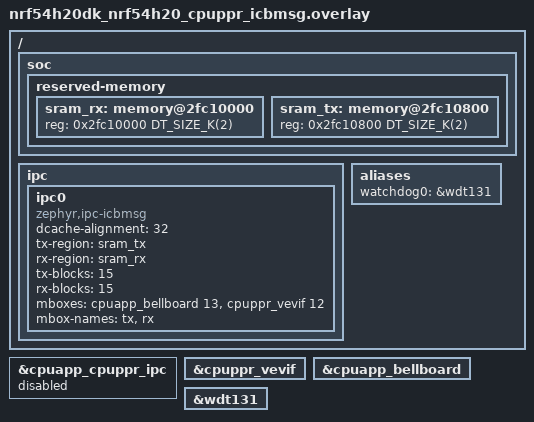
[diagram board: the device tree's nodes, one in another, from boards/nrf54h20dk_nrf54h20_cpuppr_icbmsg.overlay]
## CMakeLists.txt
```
#
# Copyright (c) 2026 Nordic Semiconductor ASA
#
# SPDX-License-Identifier: Apache-2.0
#

cmake_minimum_required(VERSION 3.20.0)

find_package(Zephyr REQUIRED HINTS $ENV{ZEPHYR_BASE})
project(ipc_service_remote)

target_include_directories(app PRIVATE ${CMAKE_CURRENT_SOURCE_DIR}/../common)

target_sources(app PRIVATE src/main.c)
```

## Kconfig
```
source "Kconfig.zephyr"

config TEST_MULTI_ENDPOINT
	bool
	default y if $(dt_nodelabel_has_compat,ipc0,$(DT_COMPAT_ZEPHYR_IPC_ICBMSG))
	default n
```

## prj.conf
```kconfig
CONFIG_IPC_SERVICE=y
CONFIG_MBOX=y
CONFIG_LOG=y
CONFIG_GPIO=n
CONFIG_CPU_LOAD=y
```

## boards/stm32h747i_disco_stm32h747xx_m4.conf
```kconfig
CONFIG_CONSOLE=y
CONFIG_UART_CONSOLE=y
CONFIG_LOG_BACKEND_UART=y

CONFIG_MBOX_STM32_HSEM=y
```

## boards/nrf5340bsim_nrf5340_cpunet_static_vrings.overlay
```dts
/*
 * Copyright (c) 2026 Nordic Semiconductor ASA
 *
 * SPDX-License-Identifier: Apache-2.0
 */

#include "nrf5340dk_nrf5340_cpunet_static_vrings.overlay"
```

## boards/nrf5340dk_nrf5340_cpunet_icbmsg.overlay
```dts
/*
 * Copyright (c) 2026 Nordic Semiconductor ASA
 *
 * SPDX-License-Identifier: Apache-2.0
 */

#include "nrf5340dk_nrf5340_cpunet_common.dtsi"

/ {
	reserved-memory {
		ranges;
		#address-cells = <1>;
		#size-cells = <1>;

		sram_rx: memory@20070000 {
			reg = <0x20070000 DT_SIZE_K(32)>;
		};

		sram_tx: memory@20078000 {
			reg = <0x20078000 DT_SIZE_K(32)>;
		};
	};

	ipc0: ipc0 {
		compatible = "zephyr,ipc-icbmsg";
		dcache-alignment = <8>;
		tx-region = <&sram_tx>;
		rx-region = <&sram_rx>;
		tx-blocks = <20>;
		rx-blocks = <20>;
		mboxes = <&mbox 0>, <&mbox 1>;
		mbox-names = "rx", "tx";
		status = "okay";
	};
};
```

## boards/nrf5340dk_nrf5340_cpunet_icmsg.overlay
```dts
/*
 * Copyright (c) 2026 Nordic Semiconductor ASA
 *
 * SPDX-License-Identifier: Apache-2.0
 */

#include "nrf5340dk_nrf5340_cpunet_common.dtsi"

/ {
	reserved-memory {
		ranges;
		#address-cells = <1>;
		#size-cells = <1>;

		sram_rx: memory@20070000 {
			reg = <0x20070000 DT_SIZE_K(32)>;
		};

		sram_tx: memory@20078000 {
			reg = <0x20078000 DT_SIZE_K(32)>;
		};
	};

	ipc0: ipc0 {
		compatible = "zephyr,ipc-icmsg";
		dcache-alignment = <8>;
		tx-region = <&sram_tx>;
		rx-region = <&sram_rx>;
		mboxes = <&mbox 0>, <&mbox 1>;
		mbox-names = "rx", "tx";
		status = "okay";
	};
};
```

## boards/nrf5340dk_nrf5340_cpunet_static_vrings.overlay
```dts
/*
 * Copyright (c) 2026 Nordic Semiconductor ASA
 *
 * SPDX-License-Identifier: Apache-2.0
 */

#include <zephyr/dt-bindings/ipc_service/static_vrings.h>

/delete-node/ &ipc0;

/ {
	reserved-memory {
		#address-cells = <1>;
		#size-cells = <1>;

		sram_ipc0: memory@20070000 {
			reg = <0x20070000 DT_SIZE_K(8)>;
		};
	};

	ipc0: ipc0 {
		compatible = "zephyr,ipc-openamp-static-vrings";
		memory-region = <&sram_ipc0>;
		mboxes = <&mbox 0>, <&mbox 1>;
		mbox-names = "rx", "tx";
		role = "remote";
		zephyr,buffer-size = <128>;
		status = "okay";
	};
};
```

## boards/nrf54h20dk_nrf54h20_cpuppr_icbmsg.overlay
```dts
/*
 * Copyright (c) 2026 Nordic Semiconductor ASA
 *
 * SPDX-License-Identifier: Apache-2.0
 */

&cpuapp_cpuppr_ipc {
	status = "disabled";
};

/ {
	soc {
		reserved-memory {
			#address-cells = <1>;
			#size-cells = <1>;

			sram_rx: memory@2fc10000 {
				reg = <0x2fc10000 DT_SIZE_K(2)>;
			};

			sram_tx: memory@2fc10800 {
				reg = <0x2fc10800 DT_SIZE_K(2)>;
			};
		};
	};

	ipc {
		ipc0: ipc0 {
			compatible = "zephyr,ipc-icbmsg";
			dcache-alignment = <32>;
			tx-region = <&sram_tx>;
			rx-region = <&sram_rx>;
			tx-blocks = <15>;
			rx-blocks = <15>;
			mboxes = <&cpuapp_bellboard 13>, <&cpuppr_vevif 12>;
			mbox-names = "tx", "rx";
			status = "okay";
		};
	};
};

&cpuppr_vevif {
	status = "okay";
};

&cpuapp_bellboard {
	status = "okay";
};

&wdt131 {
	status = "okay";
};

/ {
	aliases {
		watchdog0 = &wdt131;
	};
};
```

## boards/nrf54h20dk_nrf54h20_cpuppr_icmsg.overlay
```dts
/*
 * Copyright (c) 2026 Nordic Semiconductor ASA
 *
 * SPDX-License-Identifier: Apache-2.0
 */

ipc0: &cpuapp_cpuppr_ipc {
	compatible = "zephyr,ipc-icmsg";
	/delete-property/ tx-blocks;
	/delete-property/ rx-blocks;
};
```

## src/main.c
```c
/*
 * Copyright (c) 2026 Nordic Semiconductor ASA
 *
 * SPDX-License-Identifier: Apache-2.0
 */

#include <zephyr/kernel.h>
#include <zephyr/device.h>
#include <zephyr/sys/cpu_load.h>
#include <zephyr/ipc/ipc_service.h>
#include <zephyr/logging/log.h>
#include "common.h"

LOG_MODULE_REGISTER(remote, LOG_LEVEL_DBG);

struct test_data {
#if defined(CONFIG_MULTITHREADING)
	struct k_sem sem;
#else
	atomic_t bound_flag;
#endif
	struct ipc_ept ep;
	struct ipc_ept_cfg cfg;
};

static struct test_data ep_data[1];
static char test_name[128];
static uint32_t test_start_stamp;

static void ep_bound(void *priv)
{
	struct test_data *tdata = priv;
#if defined(CONFIG_MULTITHREADING)
	k_sem_give(&tdata->sem);
#else
	tdata->bound_flag = 1;
#endif
	LOG_INF("Ep:%s bounded", tdata->cfg.name);
}

void test_start(struct test_data *unused, const uint8_t *data, size_t len)
{
	ARG_UNUSED(unused);
	memcpy(test_name, data, len);
	if (IS_ENABLED(CONFIG_CPU_LOAD)) {
		(void)cpu_load_get(true);
	}
	test_start_stamp = k_cycle_get_32();
}

void test_end(struct test_data *unused, const uint8_t *data, size_t len)
{
	ARG_UNUSED(unused);
	ARG_UNUSED(data);
	ARG_UNUSED(len);

	uint32_t t = k_cycle_get_32() - test_start_stamp;

	t = k_cyc_to_us_floor32(t);

	printk("Test %s took %d us ", test_name, t);
	if (IS_ENABLED(CONFIG_CPU_LOAD)) {
		uint32_t load = cpu_load_get(true);

		printk("CPU load: %d.%d", load / 10, load % 10);
	}
	printk("\n");

}

static void ep_recv(const void *data, size_t len, void *priv)
{
	struct test_data *tdata = priv;
	const struct data_packet *pkt = data;

	switch (pkt->type) {
	case TYPE_RSP:
	{
		static bool once;
		int ret;

		ret = ipc_service_send(&tdata->ep, data, len);
		if ((ret < 0) && !once) {
			once = true;
			LOG_ERR("failed to send len:%d", len);
		}
		break;
	}
	case TYPE_TEST_START:
		test_start(tdata, pkt->data, len - sizeof(pkt->type));
		break;
	case TYPE_TEST_END:
		test_end(tdata, pkt->data, len - sizeof(pkt->type));
		break;
	default:
		break;
	}
}

int main(void)
{
	const struct device *ipc0 = DEVICE_DT_GET(DT_NODELABEL(ipc0));
	int ret;


	LOG_INF("IPC-service REMOTE demo started");

	ret = ipc_service_open_instance(ipc0);
	if ((ret < 0) && (ret != -EALREADY)) {
		LOG_ERR("ipc_service_open_instance() failure");
		return ret;
	}

	ep_data[0].cfg.name = "ep0";
	ep_data[0].cfg.cb.bound = ep_bound;
	ep_data[0].cfg.cb.received = ep_recv;
	ep_data[0].cfg.priv = &ep_data[0];
#if defined(CONFIG_MULTITHREADING)
	k_sem_init(&ep_data[0].sem, 0, 1);
#else
	ep_data[0].bound_flag = 0;
#endif

	ret = ipc_service_register_endpoint(ipc0, &ep_data[0].ep, &ep_data[0].cfg);
	if (ret < 0) {
		LOG_ERR("ipc_service_register_endpoint() failure");
		return ret;
	}

#if defined(CONFIG_MULTITHREADING)
	k_sem_take(&ep_data[0].sem, K_FOREVER);
#else
	while (ep_data[0].bound_flag == 0) {
	};
#endif

	k_sleep(K_FOREVER);
	return 0;
}
```
